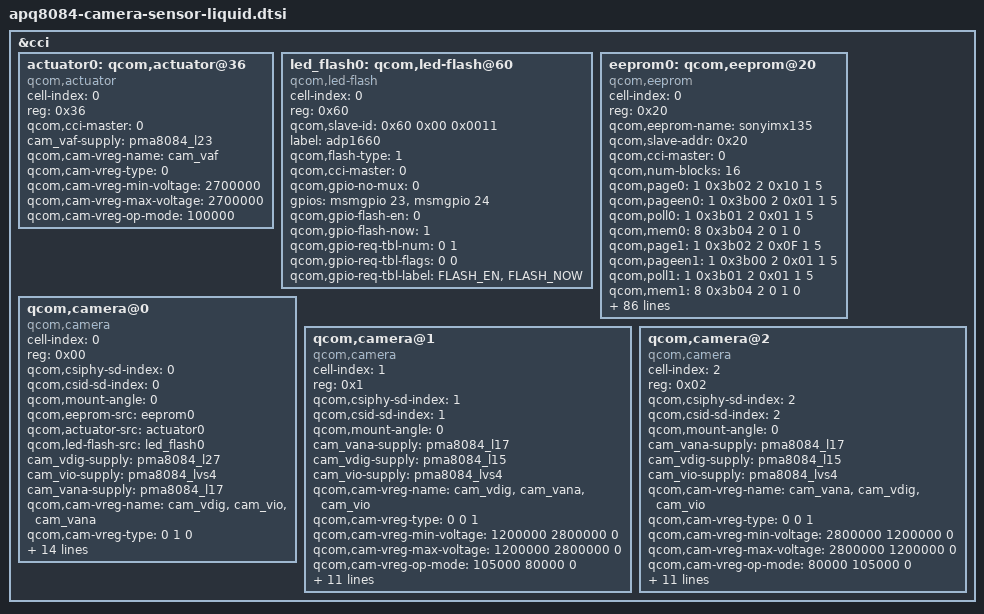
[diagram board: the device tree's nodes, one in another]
/*
 * Copyright (c) 2013-2014, The Linux Foundation. All rights reserved.
 *
 * This program is free software; you can redistribute it and/or modify
 * it under the terms of the GNU General Public License version 2 and
 * only version 2 as published by the Free Software Foundation.
 *
 * This program is distributed in the hope that it will be useful,
 * but WITHOUT ANY WARRANTY; without even the implied warranty of
 * MERCHANTABILITY or FITNESS FOR A PARTICULAR PURPOSE.  See the
 * GNU General Public License for more details.
 */

&cci {
	actuator0: qcom,actuator@36 {
		cell-index = <0>;
		reg = <0x36>;
		compatible = "qcom,actuator";
		qcom,cci-master = <0>;
		cam_vaf-supply = <&pma8084_l23>;
		qcom,cam-vreg-name = "cam_vaf";
		qcom,cam-vreg-type = <0>;
		qcom,cam-vreg-min-voltage = <2700000>;
		qcom,cam-vreg-max-voltage = <2700000>;
		qcom,cam-vreg-op-mode = <100000>;
	};

	led_flash0: qcom,led-flash@60 {
		cell-index = <0>;
		reg = <0x60>;
		qcom,slave-id = <0x60 0x00 0x0011>;
		compatible = "qcom,led-flash";
		label = "adp1660";
		qcom,flash-type = <1>;
		qcom,cci-master = <0>;
		qcom,gpio-no-mux = <0>;
		gpios = <&msmgpio 23 0>,
			<&msmgpio 24 0>;
		qcom,gpio-flash-en = <0>;
		qcom,gpio-flash-now = <1>;
		qcom,gpio-req-tbl-num = <0 1>;
		qcom,gpio-req-tbl-flags = <0 0>;
		qcom,gpio-req-tbl-label = "FLASH_EN",
			"FLASH_NOW";
	};

	eeprom0: qcom,eeprom@20 {
		cell-index = <0>;
		reg = <0x20>;
		qcom,eeprom-name = "sonyimx135";
		compatible = "qcom,eeprom";
		qcom,slave-addr = <0x20>;
		qcom,cci-master = <0>;
		qcom,num-blocks = <16>;

		qcom,page0 = <1 0x3b02 2 0x10 1 5>;
		qcom,pageen0 = <1 0x3b00 2 0x01 1 5>;
		qcom,poll0 = <1 0x3b01 2 0x01 1 5>;
		qcom,mem0 = <8 0x3b04 2 0 1 0>;

		qcom,page1 = <1 0x3b02 2 0x0F 1 5>;
		qcom,pageen1 = <1 0x3b00 2 0x01 1 5>;
		qcom,poll1 = <1 0x3b01 2 0x01 1 5>;
		qcom,mem1 = <8 0x3b04 2 0 1 0>;

		qcom,page2 = <1 0x3b02 2 0x0E 1 5>;
		qcom,pageen2 = <1 0x3b00 2 0x01 1 5>;
		qcom,poll2 = <1 0x3b01 2 0x01 1 5>;
		qcom,mem2 = <8 0x3b04 2 0 1 0>;

		qcom,page3 = <1 0x3b02 2 0x0D 1 5>;
		qcom,pageen3 = <1 0x3b00 2 0x01 1 5>;
		qcom,poll3 = <1 0x3b01 2 0x01 1 5>;
		qcom,mem3 = <8 0x3b04 2 0 1 0>;

		qcom,page4 = <1 0x3b02 2 0x12 1 5>;
		qcom,pageen4 = <1 0x3b00 2 0x01 1 5>;
		qcom,poll4 = <1 0x3b01 2 0x01 1 5>;
		qcom,mem4 = <7 0x3b09 2 0 1 0>;

		qcom,page5 = <1 0x3b02 2 0x11 1 5>;
		qcom,pageen5 = <1 0x3b00 2 0x01 1 5>;
		qcom,poll5 = <1 0x3b01 2 0x01 1 5>;
		qcom,mem5 = <7 0x3b09 2 0 1 0>;

		qcom,page6 = <1 0x3b02 2 0x10 1 5>;
		qcom,pageen6 = <1 0x3b00 2 0x01 1 5>;
		qcom,poll6 = <1 0x3b01 2 0x01 1 5>;
		qcom,mem6 = <7 0x3b09 2 0 1 0>;

		qcom,page7 = <1 0x3b02 2 0x09 1 5>;
		qcom,pageen7 = <1 0x3b00 2 0x01 1 5>;
		qcom,poll7 = <1 0x3b01 2 0x01 1 5>;
		qcom,mem7 = <7 0x3b09 2 0 1 0>;

		qcom,page8 = <1 0x3b02 2 0x01 1 5>;
		qcom,pageen8 = <1 0x3b00 2 0x01 1 5>;
		qcom,poll8 = <1 0x3b01 2 0x01 1 5>;
		qcom,mem8 = <64 0x3b04 2 0 1 0>;

		qcom,page9 = <1 0x3b02 2 0x02 1 5>;
		qcom,pageen9 = <1 0x3b00 2 0x01 1 5>;
		qcom,poll9 = <1 0x3b01 2 0x01 1 5>;
		qcom,mem9 = <64 0x3b04 2 0 1 0>;

		qcom,page10 = <1 0x3b02 2 0x03 1 5>;
		qcom,pageen10 = <1 0x3b00 2 0x01 1 5>;
		qcom,poll10 = <1 0x3b01 2 0x01 1 5>;
		qcom,mem10 = <64 0x3b04 2 0 1 0>;

		qcom,page11 = <1 0x3b02 2 0x04 1 5>;
		qcom,pageen11 = <1 0x3b00 2 0x01 1 5>;
		qcom,poll11 = <1 0x3b01 2 0x01 1 5>;
		qcom,mem11 = <64 0x3b04 2 0 1 0>;

		qcom,page12 = <1 0x3b02 2 0x05 1 5>;
		qcom,pageen12 = <1 0x3b00 2 0x01 1 5>;
		qcom,poll12 = <1 0x3b01 2 0x01 1 5>;
		qcom,mem12 = <64 0x3b04 2 0 1 0>;

		qcom,page13 = <1 0x3b02 2 0x06 1 5>;
		qcom,pageen13 = <1 0x3b00 2 0x01 1 5>;
		qcom,poll13 = <1 0x3b01 2 0x01 1 5>;
		qcom,mem13 = <64 0x3b04 2 0 1 0>;

		qcom,page14 = <1 0x3b02 2 0x07 1 5>;
		qcom,pageen14 = <1 0x3b00 2 0x01 1 5>;
		qcom,poll14 = <1 0x3b01 2 0x01 1 5>;
		qcom,mem14 = <64 0x3b04 2 0 1 0>;

		qcom,page15 = <1 0x3b02 2 0x08 1 5>;
		qcom,pageen15 = <1 0x3b00 2 0x01 1 5>;
		qcom,poll15 = <1 0x3b01 2 0x01 1 5>;
		qcom,mem15 = <56 0x3b04 2 0 1 0>;

		cam_vdig-supply = <&pma8084_l27>;
		cam_vio-supply = <&pma8084_lvs4>;
		cam_vana-supply = <&pma8084_l17>;
		qcom,cam-vreg-name = "cam_vdig", "cam_vio", "cam_vana";
		qcom,cam-vreg-type = <0 1 0>;
		qcom,cam-vreg-min-voltage = <1050000 0 2800000>;
		qcom,cam-vreg-max-voltage = <1050000 0 2800000>;
		qcom,cam-vreg-op-mode = <105000 0 80000>;
		qcom,gpio-no-mux = <0>;
		gpios = <&msmgpio 15 0>,
				<&msmgpio 36 0>,
				<&msmgpio 35 0>;
		qcom,gpio-reset = <1>;
		qcom,gpio-standby = <2>;
		qcom,gpio-req-tbl-num = <0 1 2>;
		qcom,gpio-req-tbl-flags = <1 0 0>;
		qcom,gpio-req-tbl-label = "CAMIF_MCLK",
				"CAM_RESET1",
				"CAM_STANDBY";
		qcom,gpio-set-tbl-num = <1 1>;
		qcom,gpio-set-tbl-flags = <0 2>;
		qcom,gpio-set-tbl-delay = <1000 30000>;
		qcom,csi-lane-assign = <0x4320>;
		qcom,csi-lane-mask = <0x1F>;
		qcom,cam-power-seq-type = "sensor_vreg", "sensor_vreg", "sensor_vreg",
				"sensor_gpio", "sensor_gpio" , "sensor_clk";
		qcom,cam-power-seq-val = "cam_vdig", "cam_vana", "cam_vio",
				"sensor_gpio_reset", "sensor_gpio_standby","sensor_cam_mclk";
		qcom,cam-power-seq-cfg-val = <1 1 1 1 1 24000000>;
		qcom,cam-power-seq-delay = <1 1 1 30 30 5>;
	};

	qcom,camera@0 {
		cell-index = <0>;
		compatible = "qcom,camera";
		reg = <0x00>;
		qcom,csiphy-sd-index = <0>;
		qcom,csid-sd-index = <0>;
		qcom,mount-angle = <0>;
		qcom,eeprom-src = <&eeprom0>;
		qcom,actuator-src = <&actuator0>;
		qcom,led-flash-src = <&led_flash0>;
		cam_vdig-supply = <&pma8084_l27>;
		cam_vio-supply = <&pma8084_lvs4>;
		cam_vana-supply = <&pma8084_l17>;
		qcom,cam-vreg-name = "cam_vdig", "cam_vio", "cam_vana";
		qcom,cam-vreg-type = <0 1 0>;
		qcom,cam-vreg-min-voltage = <1050000 0 2800000>;
		qcom,cam-vreg-max-voltage = <1050000 0 2800000>;
		qcom,cam-vreg-op-mode = <105000 0 80000>;
		qcom,gpio-no-mux = <0>;
		gpios = <&msmgpio 15 0>,
			<&msmgpio 36 0>,
			<&msmgpio 35 0>;
		qcom,gpio-reset = <1>;
		qcom,gpio-standby = <2>;
		qcom,gpio-req-tbl-num = <0 1 2>;
		qcom,gpio-req-tbl-flags = <1 0 0>;
		qcom,gpio-req-tbl-label = "CAMIF_MCLK0",
					  "CAM_RESET0",
					  "CAM_STANDBY0";
		qcom,sensor-position = <1>;
		qcom,sensor-mode = <1>;
		qcom,cci-master = <0>;
		status = "ok";
	};

	qcom,camera@1 {
		cell-index = <1>;
		compatible = "qcom,camera";
		reg = <0x1>;
		qcom,csiphy-sd-index = <1>;
		qcom,csid-sd-index = <1>;
		qcom,mount-angle = <0>;
		cam_vana-supply = <&pma8084_l17>;
		cam_vdig-supply = <&pma8084_l15>;
		cam_vio-supply = <&pma8084_lvs4>;
		qcom,cam-vreg-name = "cam_vdig", "cam_vana", "cam_vio";
		qcom,cam-vreg-type = <0 0 1>;
		qcom,cam-vreg-min-voltage = <1200000 2800000 0>;
		qcom,cam-vreg-max-voltage = <1200000 2800000 0>;
		qcom,cam-vreg-op-mode = <105000 80000 0>;
		qcom,gpio-no-mux = <0>;
		gpios = <&msmgpio 16 0>,
			<&msmgpio 38 0>,
			<&msmgpio 37 0>;
		qcom,gpio-reset = <1>;
		qcom,gpio-standby = <2>;
		qcom,gpio-req-tbl-num = <0 1 2>;
		qcom,gpio-req-tbl-flags = <1 0 0>;
		qcom,gpio-req-tbl-label = "CAMIF_MCLK1",
					  "CAM_RESET1",
					  "CAM_STANDBY1";
		qcom,sensor-position = <1>;
		qcom,sensor-mode = <1>;
		qcom,cci-master = <0>;
		status = "ok";
	};

	qcom,camera@2 {
		cell-index = <2>;
		compatible = "qcom,camera";
		reg = <0x02>;
		qcom,csiphy-sd-index = <2>;
		qcom,csid-sd-index = <2>;
		qcom,mount-angle = <0>;
		cam_vana-supply = <&pma8084_l17>;
		cam_vdig-supply = <&pma8084_l15>;
		cam_vio-supply = <&pma8084_lvs4>;
		qcom,cam-vreg-name =  "cam_vana", "cam_vdig", "cam_vio";
		qcom,cam-vreg-type = <0 0 1>;
		qcom,cam-vreg-min-voltage = <2800000 1200000 0>;
		qcom,cam-vreg-max-voltage = <2800000 1200000 0>;
		qcom,cam-vreg-op-mode = <80000 105000 0>;
		qcom,gpio-no-mux = <0>;
		gpios = <&msmgpio 17 0>,
			<&msmgpio 25 0>,
			<&msmgpio 120 0>;
		qcom,gpio-reset = <1>;
		qcom,gpio-standby = <2>;
		qcom,gpio-req-tbl-num = <0 1 2>;
		qcom,gpio-req-tbl-flags = <1 0 0>;
		qcom,gpio-req-tbl-label = "CAMIF_MCLK2",
					  "CAM_RESET2",
					  "CAM_STANDBY2";
		qcom,sensor-position = <1>;
		qcom,sensor-mode = <1>;
		qcom,cci-master = <0>;
		status = "ok";
	};
};
